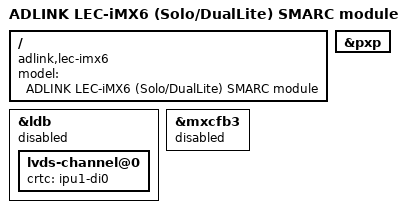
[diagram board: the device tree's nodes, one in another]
// SPDX-License-Identifier: GPL-2.0
//
// Copyright (C) 2014-2016 LiPPERT ADLINK Technology GmbH
// Copyright (C) 2013 Freescale Semiconductor, Inc.

/* The i.MX6 Solo/DualLite only has 1 IPU i.e. can only operate 2 of the 3
 * display options at the same time. lec-imx6.dtsi assigns the IPU's 2 DIs such
 * that HDMI always works, whereas parallel RGB and LVDS compete for the same
 * DI. The following option leaves only one of them enabled. (The Quad/Dual DTS
 * maps LVDS to the 2nd IPU, enabling all displays simultaneously.) */
#define CONFIG_SOLO_LVDS       0

/dts-v1/;

#include "../nxp/imx/imx6dl.dtsi"
#include "lec-imx6.dtsi"

/ {
	model = "ADLINK LEC-iMX6 (Solo/DualLite) SMARC module";
	compatible = "adlink,lec-imx6", "fsl,imx6dl";
};

&ldb {	/* LVDS (see fb in lec-imx6.dtsi) */
	lvds-channel@0 {
		crtc = "ipu1-di0";
	};
};

#if CONFIG_SOLO_LVDS
&mxcfb2 {	/* parallel RGB */
#else
&mxcfb3 {	/* LVDS */
#endif
	status = "disabled";
};

#if CONFIG_SOLO_LVDS
&rgb {	/* parallel RGB */
#else
&ldb {	/* LVDS */
#endif
	status = "disabled";
};

&pxp {
	status = "okay";
};
